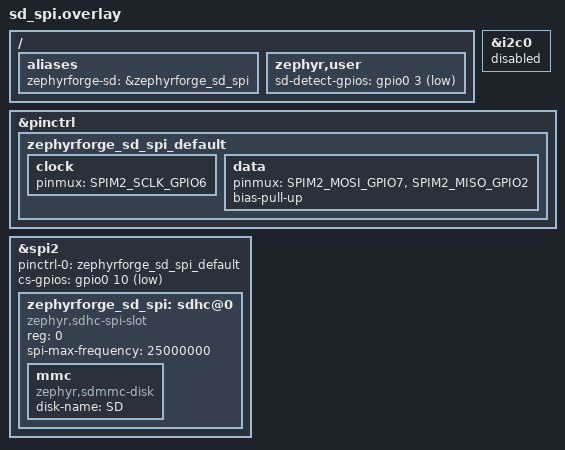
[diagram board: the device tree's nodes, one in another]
/*
 * ESP32-C6 SD over SPI2: GPIO6 SCK, GPIO7 MOSI, GPIO2 MISO, GPIO10 CS, GPIO3 card detect (active low).
 */
#include <zephyr/dt-bindings/gpio/gpio.h>
#include <dt-bindings/pinctrl/esp32c6-pinctrl.h>

/ {
	aliases {
		zephyrforge-sd = &zephyrforge_sd_spi;
	};
	zephyr,user {
		sd-detect-gpios = <&gpio0 3 (GPIO_ACTIVE_LOW | GPIO_PULL_UP)>;
	};
};

&i2c0 {
	status = "disabled";
};

&pinctrl {
	zephyrforge_sd_spi_default: zephyrforge_sd_spi_default {
		clock {
			pinmux = <SPIM2_SCLK_GPIO6>;
		};
		data {
			pinmux = <SPIM2_MOSI_GPIO7>, <SPIM2_MISO_GPIO2>;
			bias-pull-up;
		};
	};
};

&spi2 {
	status = "okay";
	pinctrl-0 = <&zephyrforge_sd_spi_default>;
	pinctrl-names = "default";
	cs-gpios = <&gpio0 10 GPIO_ACTIVE_LOW>;
	zephyrforge_sd_spi: sdhc@0 {
		compatible = "zephyr,sdhc-spi-slot";
		reg = <0>;
		spi-max-frequency = <25000000>;
		mmc {
			compatible = "zephyr,sdmmc-disk";
			disk-name = "SD";
			status = "okay";
		};
	};
};
